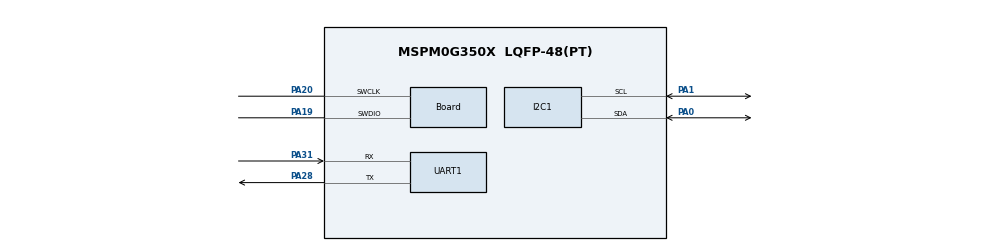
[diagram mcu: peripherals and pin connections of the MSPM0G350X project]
/**
 * @cliArgs --device "MSPM0G350X" --part "Default" --package "LQFP-48(PT)" --product "mspm0_sdk@2.05.01.00"
 * @versions {"tool":"1.26.2+4477"}
 */

/**
 * Import the modules used in this configuration.
 */
const GPIO          = scripting.addModule("/ti/driverlib/GPIO", {}, false);
const GPIO1         = GPIO.addInstance();
const I2C           = scripting.addModule("/ti/driverlib/I2C", {}, false);
const I2C1          = I2C.addInstance();
const SYSCTL        = scripting.addModule("/ti/driverlib/SYSCTL");
const UART          = scripting.addModule("/ti/driverlib/UART", {}, false);
const UART1         = UART.addInstance();
const ProjectConfig = scripting.addModule("/ti/project_config/ProjectConfig");

/**
 * Write custom configuration values to the imported modules.
 */
GPIO1.$name                          = "GPIO0";
GPIO1.associatedPins[0].$name        = "LED";
GPIO1.associatedPins[0].assignedPort = "PORTA";
GPIO1.associatedPins[0].assignedPin  = "14";

const Board                       = scripting.addModule("/ti/driverlib/Board", {}, false);
Board.peripheral.$assign          = "DEBUGSS";
Board.peripheral.swclkPin.$assign = "PA20";
Board.peripheral.swdioPin.$assign = "PA19";

I2C1.basicEnableController             = true;
I2C1.intController                     = ["ARBITRATION_LOST","NACK","RXFIFO_TRIGGER","RX_DONE","TX_DONE"];
I2C1.$name                             = "I2C";
I2C1.peripheral.$assign                = "I2C0";
I2C1.peripheral.sdaPin.$assign         = "PA0";
I2C1.peripheral.sclPin.$assign         = "PA1";
I2C1.sdaPinConfig.hideOutputInversion  = scripting.forceWrite(false);
I2C1.sdaPinConfig.onlyInternalResistor = scripting.forceWrite(false);
I2C1.sdaPinConfig.passedPeripheralType = scripting.forceWrite("Digital");
I2C1.sdaPinConfig.$name                = "ti_driverlib_gpio_GPIOPinGeneric2";
I2C1.sclPinConfig.hideOutputInversion  = scripting.forceWrite(false);
I2C1.sclPinConfig.onlyInternalResistor = scripting.forceWrite(false);
I2C1.sclPinConfig.passedPeripheralType = scripting.forceWrite("Digital");
I2C1.sclPinConfig.$name                = "ti_driverlib_gpio_GPIOPinGeneric3";

SYSCTL.forceDefaultClkConfig = true;
SYSCTL.peripheral.$assign    = "SYSCTL";

UART1.$name                            = "UART0";
UART1.enabledDMARXTriggers             = "DL_UART_DMA_INTERRUPT_RX";
UART1.peripheral.$assign               = "UART0";
UART1.peripheral.rxPin.$assign         = "PA31";
UART1.peripheral.txPin.$assign         = "PA28";
UART1.txPinConfig.direction            = scripting.forceWrite("OUTPUT");
UART1.txPinConfig.hideOutputInversion  = scripting.forceWrite(false);
UART1.txPinConfig.onlyInternalResistor = scripting.forceWrite(false);
UART1.txPinConfig.passedPeripheralType = scripting.forceWrite("Digital");
UART1.txPinConfig.$name                = "ti_driverlib_gpio_GPIOPinGeneric0";
UART1.rxPinConfig.hideOutputInversion  = scripting.forceWrite(false);
UART1.rxPinConfig.onlyInternalResistor = scripting.forceWrite(false);
UART1.rxPinConfig.passedPeripheralType = scripting.forceWrite("Digital");
UART1.rxPinConfig.$name                = "ti_driverlib_gpio_GPIOPinGeneric1";
UART1.DMA_CHANNEL_RX.$name             = "DMA_CH0";

ProjectConfig.migrationCondition = true;

/**
 * Pinmux solution for unlocked pins/peripherals. This ensures that minor changes to the automatic solver in a future
 * version of the tool will not impact the pinmux you originally saw.  These lines can be completely deleted in order to
 * re-solve from scratch.
 */
GPIO1.associatedPins[0].pin.$suggestSolution     = "PA14";
UART1.DMA_CHANNEL_RX.peripheral.$suggestSolution = "DMA_CH0";
